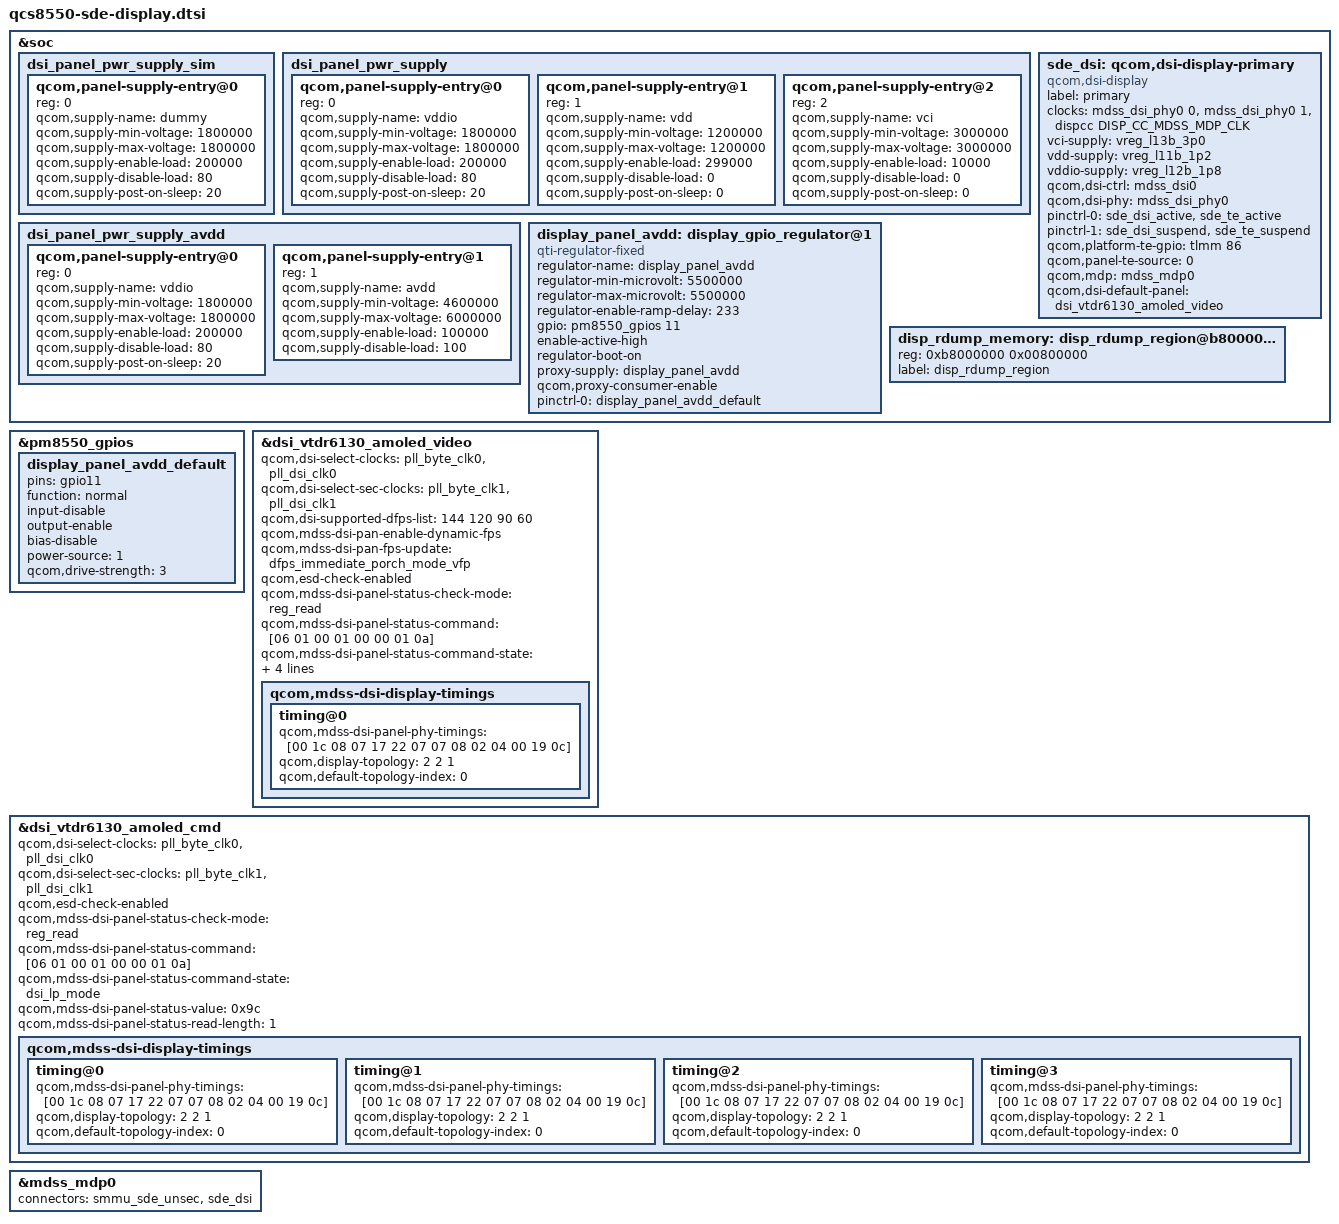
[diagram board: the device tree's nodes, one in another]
// SPDX-License-Identifier: BSD-3-Clause
/*
 * Copyright (c) 2024 Qualcomm Innovation Center, Inc. All rights reserved.
 */

#include "dsi-panel-vtdr6130-dsc-fhd-plus-video.dtsi"
#include "dsi-panel-vtdr6130-dsc-fhd-plus-cmd.dtsi"

#include "qcs8550-sde-display-pinctrl.dtsi"

&soc {
	dsi_panel_pwr_supply_sim: dsi_panel_pwr_supply_sim {
		#address-cells = <1>;
		#size-cells = <0>;

		qcom,panel-supply-entry@0 {
			reg = <0>;
			qcom,supply-name = "dummy";
			qcom,supply-min-voltage = <1800000>;
			qcom,supply-max-voltage = <1800000>;
			qcom,supply-enable-load = <200000>;
			qcom,supply-disable-load = <80>;
			qcom,supply-post-on-sleep = <20>;
		};
	};

	dsi_panel_pwr_supply: dsi_panel_pwr_supply {
		#address-cells = <1>;
		#size-cells = <0>;

		qcom,panel-supply-entry@0 {
			reg = <0>;
			qcom,supply-name = "vddio";
			qcom,supply-min-voltage = <1800000>;
			qcom,supply-max-voltage = <1800000>;
			qcom,supply-enable-load = <200000>;
			qcom,supply-disable-load = <80>;
			qcom,supply-post-on-sleep = <20>;
		};

		qcom,panel-supply-entry@1 {
			reg = <1>;
			qcom,supply-name = "vdd";
			qcom,supply-min-voltage = <1200000>;
			qcom,supply-max-voltage = <1200000>;
			qcom,supply-enable-load = <299000>;
			qcom,supply-disable-load = <0>;
			qcom,supply-post-on-sleep = <0>;
		};

		qcom,panel-supply-entry@2 {
			reg = <2>;
			qcom,supply-name = "vci";
			qcom,supply-min-voltage = <3000000>;
			qcom,supply-max-voltage = <3000000>;
			qcom,supply-enable-load = <10000>;
			qcom,supply-disable-load = <0>;
			qcom,supply-post-on-sleep = <0>;
		};
	};

	dsi_panel_pwr_supply_avdd: dsi_panel_pwr_supply_avdd {
		#address-cells = <1>;
		#size-cells = <0>;

		qcom,panel-supply-entry@0 {
			reg = <0>;
			qcom,supply-name = "vddio";
			qcom,supply-min-voltage = <1800000>;
			qcom,supply-max-voltage = <1800000>;
			qcom,supply-enable-load = <200000>;
			qcom,supply-disable-load = <80>;
			qcom,supply-post-on-sleep = <20>;
		};

		qcom,panel-supply-entry@1 {
			reg = <1>;
			qcom,supply-name = "avdd";
			qcom,supply-min-voltage = <4600000>;
			qcom,supply-max-voltage = <6000000>;
			qcom,supply-enable-load = <100000>;
			qcom,supply-disable-load = <100>;
		};
	};

	sde_dsi: qcom,dsi-display-primary {
		compatible = "qcom,dsi-display";
		label = "primary";

		clocks = <&mdss_dsi_phy0 0>,
		 <&mdss_dsi_phy0 1>,
		 /*
		  * Currently the dsi clock handles are under the dsi
		  * controller DT node. As soon as the controller probe
		  * finishes, the dispcc sync state can get called before
		  * the dsi_display probe potentially disturbing the clock
		  * votes for cont_splash use case. Hence we are no longer
		  * protected by the component model in this case against the
		  * disp cc sync state getting triggered after the dsi_ctrl
		  * probe. To protect against this incorrect sync state trigger
		  * add this dummy MDP clk vote handle to the dsi_display
		  * DT node. Since the dsi_display driver does not parse
		  * MDP clock nodes, no actual vote shall be added and this
		  * change is done just to satisfy sync state requirements.
		  */
		 <&dispcc DISP_CC_MDSS_MDP_CLK>;
		clock-names = "pll_byte_clk0", "pll_dsi_clk0",
			      "mdp_core_clk";

		vci-supply = <&vreg_l13b_3p0>;
		vdd-supply = <&vreg_l11b_1p2>;
		vddio-supply = <&vreg_l12b_1p8>;

		qcom,dsi-ctrl = <&mdss_dsi0>;
		qcom,dsi-phy = <&mdss_dsi_phy0>;

		pinctrl-names = "panel_active", "panel_suspend";
		pinctrl-0 = <&sde_dsi_active &sde_te_active>;
		pinctrl-1 = <&sde_dsi_suspend &sde_te_suspend>;

		qcom,platform-te-gpio = <&tlmm 86 0>;
		qcom,panel-te-source = <0>;

		qcom,mdp = <&mdss_mdp0>;

		qcom,dsi-default-panel = <&dsi_vtdr6130_amoled_video>;
	};
};

&pm8550_gpios {
	display_panel_avdd_default: display_panel_avdd_default {
		pins = "gpio11";
		function = "normal";
		input-disable;
		output-enable;
		bias-disable;
		power-source = <1>;
		qcom,drive-strength = <3>;
	};
};

&soc {
	display_panel_avdd: display_gpio_regulator@1 {
		compatible = "qti-regulator-fixed";
		regulator-name = "display_panel_avdd";
		regulator-min-microvolt = <5500000>;
		regulator-max-microvolt = <5500000>;
		regulator-enable-ramp-delay = <233>;
		gpio = <&pm8550_gpios 11 0>;
		enable-active-high;
		regulator-boot-on;
		proxy-supply = <&display_panel_avdd>;
		qcom,proxy-consumer-enable;
		pinctrl-names = "default";
		pinctrl-0 = <&display_panel_avdd_default>;
	};

	disp_rdump_memory: disp_rdump_region@b8000000 {
		reg = <0xb8000000 0x00800000>;
		label = "disp_rdump_region";
	};
};

&dsi_vtdr6130_amoled_video {
	qcom,dsi-select-clocks = "pll_byte_clk0", "pll_dsi_clk0";
	qcom,dsi-select-sec-clocks = "pll_byte_clk1", "pll_dsi_clk1";
	qcom,dsi-supported-dfps-list = <144 120 90 60>;
	qcom,mdss-dsi-pan-enable-dynamic-fps;
	qcom,mdss-dsi-pan-fps-update = "dfps_immediate_porch_mode_vfp";

	qcom,esd-check-enabled;
	qcom,mdss-dsi-panel-status-check-mode = "reg_read";
	qcom,mdss-dsi-panel-status-command = [06 01 00 01 00 00 01 0a];
	qcom,mdss-dsi-panel-status-command-state = "dsi_lp_mode";
	qcom,mdss-dsi-panel-status-value = <0x9c>;
	qcom,mdss-dsi-panel-status-read-length = <1>;

	qcom,mdss-dsi-panel-hdr-enabled;

	qcom,mdss-dsi-display-timings {
		timing@0 {
			qcom,mdss-dsi-panel-phy-timings = [00 1c 08 07 17 22 07
				07 08 02 04 00 19 0c];
			qcom,display-topology = <2 2 1>;
			qcom,default-topology-index = <0>;
		};
	};
};

&dsi_vtdr6130_amoled_cmd {
	qcom,dsi-select-clocks = "pll_byte_clk0", "pll_dsi_clk0";
	qcom,dsi-select-sec-clocks = "pll_byte_clk1", "pll_dsi_clk1";

	qcom,esd-check-enabled;
	qcom,mdss-dsi-panel-status-check-mode = "reg_read";
	qcom,mdss-dsi-panel-status-command = [06 01 00 01 00 00 01 0a];
	qcom,mdss-dsi-panel-status-command-state = "dsi_lp_mode";
	qcom,mdss-dsi-panel-status-value = <0x9c>;
	qcom,mdss-dsi-panel-status-read-length = <1>;

	qcom,mdss-dsi-display-timings {
		timing@0 {
			qcom,mdss-dsi-panel-phy-timings = [00 1c 08 07 17 22 07
				07 08 02 04 00 19 0c];
			qcom,display-topology = <2 2 1>;
			qcom,default-topology-index = <0>;
		};
		timing@1 {
			qcom,mdss-dsi-panel-phy-timings = [00 1c 08 07 17 22 07
				07 08 02 04 00 19 0c];
			qcom,display-topology = <2 2 1>;
			qcom,default-topology-index = <0>;
		};
		timing@2 {
			qcom,mdss-dsi-panel-phy-timings = [00 1c 08 07 17 22 07
				07 08 02 04 00 19 0c];
			qcom,display-topology = <2 2 1>;
			qcom,default-topology-index = <0>;
		};
		timing@3 {
			qcom,mdss-dsi-panel-phy-timings = [00 1c 08 07 17 22 07
				07 08 02 04 00 19 0c];
			qcom,display-topology = <2 2 1>;
			qcom,default-topology-index = <0>;
		};
	};
};

&mdss_mdp0 {
	connectors = <&smmu_sde_unsec &sde_dsi>;
};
